# ATSAMG54 register map
Vendor: Microchip Technology; Series: SAMG54; File version: 0
CPU: CM4 r0p1, little endian, MPU, FPU, 4 interrupt priority bits
Registers are 32-bit, read-write, reset 0x0 unless marked. A register's access mark holds for its fields unless they carry their own. Offsets are from the block's base; [hi:lo] are bit positions; 'fields as' and 'values as' point back to an identical list.

## SUPC — Supply Controller
Base 0x400E1410; register names take the prefix SUPC_
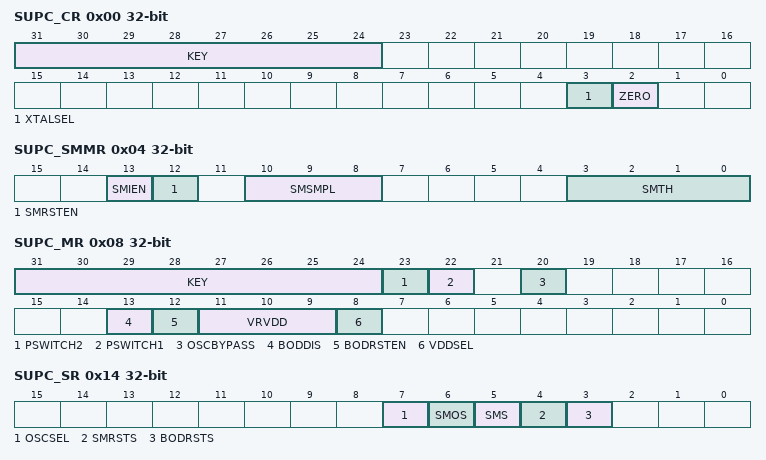
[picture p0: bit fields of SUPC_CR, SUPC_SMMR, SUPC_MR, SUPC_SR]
0x00 SUPC_CR wo — Supply Controller Control Register
  [31:24] KEY — Password
    165=PASSWD (Writing any other value in this field aborts the write operation.Always reads as 0.)
  [3] XTALSEL — Crystal Oscillator Select
    0=NO_EFFECT; 1=CRYSTAL_SEL (If KEY is correct, switches the slow clock on the crystal oscillator output.)
  [2] ZERO — This bit must always be written to 0.
0x04 SUPC_SMMR — Supply Controller Supply Monitor Mode Register
  [13] SMIEN — Supply Monitor Interrupt Enable
    0=NOT_ENABLE (The SUPC interrupt signal is not affected when a supply monitor detection occurs.); 1=ENABLE (The SUPC interrupt signal is asserted when a supply monitor detection occurs.)
  [12] SMRSTEN — Supply Monitor Reset Enable
    0=NOT_ENABLE (The core reset signal vddcore_nreset is not affected when a supply monitor detection occurs.); 1=ENABLE (The core reset signal vddcore_nreset is asserted when a supply monitor detection occurs.)
  [10:8] SMSMPL — Supply Monitor Sampling Period
    0=SMD (Supply Monitor disabled); 1=CSM (Continuous Supply Monitor); 2=_32SLCK (Supply Monitor enables one SLCK period every 32 SLCK periods); 3=_256SLCK (Supply Monitor enables one SLCK period every 256 SLCK periods); 4=_2048SLCK (Supply Monitor enables one SLCK period every 2,048 SLCK periods)
  [3:0] SMTH — Supply Monitor Threshold
    0=V1P6 (1.6 V); 1=V1P72 (1.72 V); 2=V1P84 (1.84 V); 3=V1P96 (1.96 V); 4=V2P08 (2.08 V); 5=V2P2 (2.2 V); 6=V2P32 (2.32 V); 7=V2P44 (2.44 V); 8=V2P56 (2.56 V); 9=V2P68 (2.68 V); 10=V2P8 (2.8 V); 11=V2P92 (2.92 V); 12=V3P04 (3.04 V); 13=V3P16 (3.16 V); 14=V3P28 (3.28 V); 15=V3P4 (3.4 V)
0x08 SUPC_MR — Supply Controller Mode Register
  [31:24] KEY — Password Key
    values as SUPC_CR.KEY
  [23] PSWITCH2 — SRAM2 Power Switch
    0=OFF (The SRAM2 is not powered.); 1=ON (The SRAM2 is powered.)
  [22] PSWITCH1 — SRAM1 Power Switch
    0=OFF (The SRAM1 is not powered.); 1=ON (The SRAM1 is powered.)
  [20] OSCBYPASS — Oscillator Bypass
    0=NO_EFFECT (No effect. Clock selection depends on XTALSEL value.); 1=BYPASS (The 32 kHz crystal oscillator is bypassed if XTALSEL=1. OSCBYPASS must be set prior to write XTALSEL=1.)
  [13] BODDIS — POR Core Disable
    0=ENABLE (The core brownout detector is enabled.); 1=DISABLE (The core brownout detector is disabled.)
  [12] BODRSTEN — POR Core Reset Enable
    0=NOT_ENABLE (The core reset signal vddcore_nreset is not affected when a brownout detection occurs.); 1=ENABLE (The core reset signal vddcore_nreset is asserted when a brownout detection occurs.)
  [11:9] VRVDD — VRVDD Field Selection
    0=FACTORY (The voltage regulator output value is the factory-programmed value.); 1=USER_VRVDD (The voltage regulator output value is defined by the value programmed in the field VRVDD.)
  [8] VDDSEL — VRVDD Field Selection
    values as VRVDD
0x14 SUPC_SR ro — Supply Controller Status Register
  [7] OSCSEL — 32-kHz Oscillator Selection Status
    0=RC (The slow clock SLCK is generated by the embedded 32 kHz RC oscillator.); 1=CRYST (The slow clock SLCK is generated by the 32 kHz crystal oscillator.)
  [6] SMOS — Supply Monitor Output Status
    0=HIGH (The supply monitor detected VDDIO higher than its threshold at its last measurement.); 1=LOW (The supply monitor detected VDDIO lower than its threshold at its last measurement.)
  [5] SMS — Supply Monitor Status (cleared on read)
    0=NO (No supply monitor detection since the last read of SUPC_SR.); 1=PRESENT (At least one supply monitor detection since the last read of SUPC_SR.)
  [4] SMRSTS — Supply Monitor Reset Status (cleared on read)
    0=NO (No supply monitor detection has generated a core reset since the last read of SUPC_SR.); 1=PRESENT (At least one supply monitor detection has generated a core reset since the last read of SUPC_SR.)
  [3] BODRSTS — Brownout Detector Reset Status (cleared on read)
    0=NO (No core brownout rising edge event has been detected since the last read of SUPC_SR.); 1=PRESENT (At least one brownout output rising edge event has been detected since the last read of SUPC_SR.)
